# SN32F770 register map
Vendor: SONiX Technology Co., Ltd.; Series: SN32F770; File version: 1.4
CPU: CM0 r0p0, little endian, no MPU, no FPU, 2 interrupt priority bits
Registers are 32-bit, read-write, reset 0x0 unless marked. A register's access mark holds for its fields unless they carry their own. Offsets are from the block's base; [hi:lo] are bit positions; {n}, {i} and the like mark numbered series.

## SN_CT16B0 — 16-bit Timer 0 with Capture function
Base 0x40000000
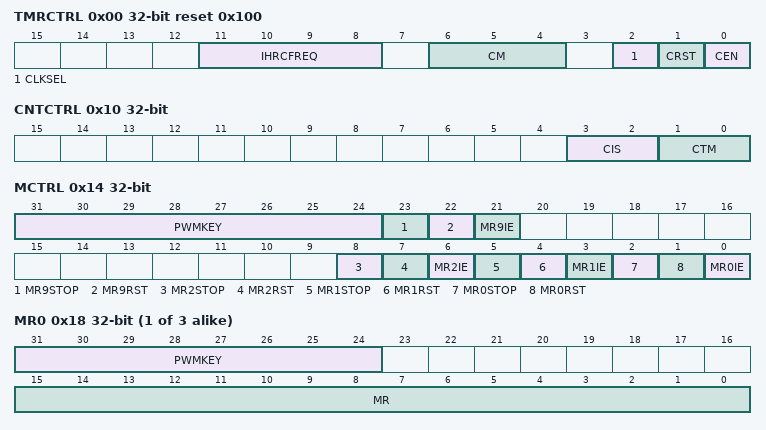
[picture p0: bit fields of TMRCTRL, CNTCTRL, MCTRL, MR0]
0x00 TMRCTRL reset 0x100 — Offset:0x00 CT16Bn Timer Control Register
  [11:8] IHRCFREQ — Internal high-speed clock frequency for CT16B0 PCLK
    1=IHRC (Enable IHRC 12MHz for CT16B0 PCLK); 2=IHRC (Enable IHRC 24MHz for CT16B0 PCLK); 4=IHRC (Enable IHRC 48MHz for CT16B0 PCLK); 8=IHRC (Enable IHRC 96MHz for CT16B0 PCLK)
  [6:4] CM — Counting mode selection
    0=Counting mode (Edge-aligned Up-counting mode); 1=Counting mode (Edge-aligned Down-counting mode); 2=Counting mode (Center-aligned mode 1. The match interrupt flag is set during the down-counting period); 4=Counting mode (Center-aligned mode 2. The match interrupt flag is set during the up- counting period); 6=Counting mode (Center-aligned mode 3. The match interrupt flag is set during both up-counting and down-counting period)
  [2] CLKSEL — Clock source
    0=HCLK (CT16Bn clock source=HCLK); 1=IHRC (CT16Bn clock source=IHRC)
  [1] CRST — Counter Reset
    0=Disable; 1=Reset Counter (Timer Counter and the Prescale Counter are synchronously reset on the next positive edge of PCLK)
  [0] CEN — Counter enable
    0=Disable counter; 1=Enable Timer Counter and Prescale Counter for counting
0x04 TC — Offset:0x04 CT16Bn Timer Counter Register
  [15:0] TC — Timer Counter
0x08 PRE — Offset:0x08 CT16Bn Prescale Register
  [7:0] PRE — Prescaler
0x0C PC — Offset:0x0C CT16Bn Prescale Counter Register
  [7:0] PC — Prescaler Counter
0x10 CNTCTRL — Offset:0x10 CT16Bn Counter Control Register
  [3:2] CIS — Counter Input Select
    0=CT16Bn_CAP0
  [1:0] CTM — Counter/Timer Mode
    0=Timer Mode: every rising PCLK edge; 1=Counter Mode:TC is incremented on rising edges on the CAP0 input selected by CIS bits; 2=Counter Mode:TC is incremented on falling edges on the CAP0 input selected by CIS bits; 3=Counter Mode:TC is incremented on both edges on the CAP0 input selected by CIS bits
0x14 MCTRL — Offset:0x14 CT16Bn Match Control Register
  [31:24] PWMKEY wo — PWM register key.
  [23] MR9STOP — Stop TC and PC and clear CEN bit when MR9 matches TC
    0=Disable; 1=Enable (Stop TC and PC and clear CEN bit when MR9 matches TC)
  [22] MR9RST — Enable reset TC when MR9 matches TC
    0=Disable; 1=Enable (Reset TC when MR9 matches TC)
  [21] MR9IE — Enable generating an interrupt based on CM[2:0] when MR9 matches the value in the TC
    0=Disable; 1=Enable (Generating an interrupt when MR9 matches TC)
  [8] MR2STOP — Stop TC and PC and clear CEN bit when MR2 matches TC
    0=Disable; 1=Enable (Stop TC and PC and clear CEN bit when MR2 matches TC)
  [7] MR2RST — Enable reset TC when MR2 matches TC
    0=Disable; 1=Enable (Reset TC when MR2 matches TC)
  [6] MR2IE — Enable generating an interrupt when MR2 matches TC
    0=Disable; 1=Enable (Generating an interrupt when MR2 matches TC)
  [5] MR1STOP — Stop TC and PC and clear CEN bit when MR1 matches TC
    0=Disable; 1=Enable (Stop TC and PC and clear CEN bit when MR1 matches TC)
  [4] MR1RST — Enable reset TC when MR1 matches TC
    0=Disable; 1=Enable (Reset TC when MR1 matches TC)
  [3] MR1IE — Enable generating an interrupt when MR1 matches TC
    0=Disable; 1=Enable (Generating an interrupt when MR1 matches TC)
  [2] MR0STOP — Stop TC and PC and clear CEN bit when MR0 matches TC
    0=Disable; 1=Enable (Stop TC and PC and clear CEN bit when MR0 matches TC)
  [1] MR0RST — Enable reset TC when MR0 matches TC
    0=Disable; 1=Enable (Reset TC when MR0 matches TC)
  [0] MR0IE — Enable generating an interrupt when MR0 matches TC
    0=Disable; 1=Enable (Generating an interrupt when MR0 matches TC)
{0x18+4i} MR{i} (i=0..2) — Offset:{0x18+4i} CT16Bn MR{i} Register
  [31:24] PWMKEY wo — PWM register key
  [15:0] MR — Timer counter match value
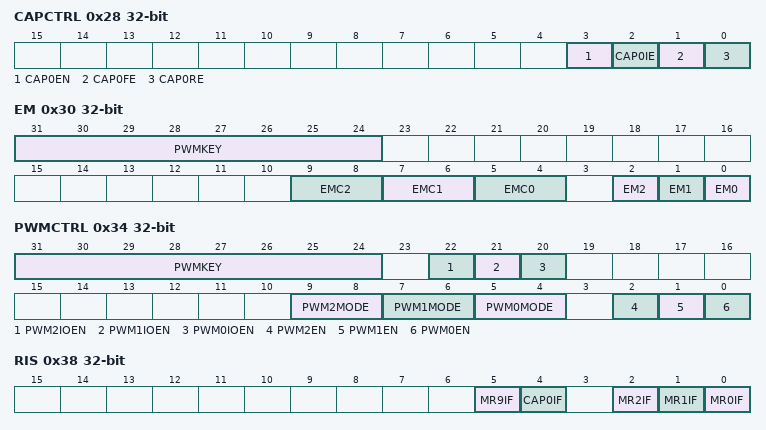
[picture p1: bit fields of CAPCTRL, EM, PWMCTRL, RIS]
0x28 CAPCTRL — Offset:0x28 CT16Bn Capture Control Register
  [3] CAP0EN — CAP0 function enable
    0=Disable; 1=Enable CAP0 function
  [2] CAP0IE — Interrupt on CT16Bn_CAP0 event
    0=Disable; 1=Enable (A CAP0 load due to a CT16Bn_CAP0 event will generate an interrupt.)
  [1] CAP0FE — Capture on CT16Bn_CAP0 falling edge
    0=Disable; 1=Enable (A sequence of 1 then 0 on CT16Bn_CAP0 will cause CAP0 to be loaded with the contents of TC.)
  [0] CAP0RE — Capture on CT16Bn_CAP0 rising edge
    0=Disable; 1=Enable (A sequence of 0 then 1 on CT16Bn_CAP0 will cause CAP0 to be loaded with the contents of TC.)
0x2C CAP0 ro — Offset:0x2C CT16Bn CAP0 Register
  [15:0] CAP0 — Timer counter capture value
0x30 EM — Offset:0x30 CT16Bn External Match Register
  [31:24] PWMKEY wo — PWM register key.
  [9:8] EMC2 — CT16Bn_PWM2 functionality when the TC matches MR2
    0=Do Nothing; 1=Low (CT16Bn_PWM2 pin is LOW); 2=High (CT16Bn_PWM2 pin is HIGH); 3=Toggle CT16Bn_PWM2 pin
  [7:6] EMC1 — CT16Bn_PWM1 functionality when the TC matches MR1
    0=Do Nothing; 1=Low (CT16Bn_PWM1 pin is LOW); 2=High (CT16Bn_PWM1 pin is HIGH); 3=Toggle CT16Bn_PWM1 pin
  [5:4] EMC0 — CT16Bn_PWM0 functionality when the TC matches MR0
    0=Do Nothing; 1=Low (CT16Bn_PWM0 pin is LOW); 2=High (CT16Bn_PWM0 pin is HIGH); 3=Toggle CT16Bn_PWM0 pin
  [2] EM2 — When the TC doesn't match MR2 and EMC2 is not 0, this bit will drive the state of CT16Bn_PWM2 output.
  [1] EM1 — When the TC doesn't match MR1 and EMC1 is not 0, this bit will drive the state of CT16Bn_PWM1 output.
  [0] EM0 — When the TC doesn't match MR0 and EMC0 is not 0, this bit will drive the state of CT16Bn_PWM0 output.
0x34 PWMCTRL — Offset:0x34 CT16Bn PWM Control Register
  [31:24] PWMKEY wo — PWM register key.
  [22] PWM2IOEN — CT16Bn_PWM2/GPIO selection
    0=Disable (CT16Bn_PWM2 pin is act as GPIO); 1=Enable (CT16Bn_PWM2 pin act as match output, and output depends on PWM2EN bit)
  [21] PWM1IOEN — CT16Bn_PWM1/GPIO selection
    0=Disable (CT16Bn_PWM1 pin is act as GPIO); 1=Enable (CT16Bn_PWM1 pin act as match output, and output depends on PWM1EN bit)
  [20] PWM0IOEN — CT16Bn_PWM0/GPIO selection
    0=Disable (CT16Bn_PWM0 pin is act as GPIO); 1=Enable (CT16Bn_PWM0 pin act as match output, and output depends on PWM0EN bit)
  [9:8] PWM2MODE — PWM2 output mode
    0=PWM mode 1 (During up-counting, PWM2 is 0 when TC is less than MR2.); 1=PWM mode 2 (During up-counting, PWM2 is 1 when TC is less than MR2.); 2=Force 0 (PWM2 is forced to 0); 3=Force 1 (PWM2 is forced to 1)
  [7:6] PWM1MODE — PWM1 output mode
    0=PWM mode 1 (During up-counting, PWM1 is 0 when TC is less than MR1.); 1=PWM mode 2 (During up-counting, PWM1 is 1 when TC is less than MR1.); 2=Force 0 (PWM1 is forced to 0); 3=Force 1 (PWM1 is forced to 1)
  [5:4] PWM0MODE — PWM0 output mode
    0=PWM mode 1 (During up-counting, PWM0 is 0 when TC is less than MR0.); 1=PWM mode 2 (During up-counting, PWM0 is 1 when TC is less than MR0.); 2=Force 0 (PWM0 is forced to 0); 3=Force 1 (PWM0 is forced to 1)
  [2] PWM2EN — PWM2 enable
    0=Disable (CT16Bn_PWM2 is controlled by EMC2); 1=Enable PWM mode for CT16Bn_PWM2
  [1] PWM1EN — PWM1 enable
    0=Disable (CT16Bn_PWM1 is controlled by EMC1); 1=Enable PWM mode for CT16Bn_PWM1
  [0] PWM0EN — PWM0 enable
    0=Disable (CT16Bn_PWM0 is controlled by EMC0); 1=Enable PWM mode for CT16Bn_PWM0
0x38 RIS ro — Offset:0x38 CT16Bn Raw Interrupt Status Register
  [5] MR9IF — Match channel 9 interrupt flag
    0=No (No interrupt on match channel 9); 1=Met interrupt requirements (Interrupt requirements met on match channel 9)
  [4] CAP0IF — Capture channel 0 interrupt flag
    0=No (No interrupt on CAP0); 1=Met interrupt requirements (Interrupt requirements met on CAP0)
  [2] MR2IF — Match channel 2 interrupt flag
    0=No (No interrupt on match channel 2); 1=Met interrupt requirements (Interrupt requirements met on match channel 2)
  [1] MR1IF — Match channel 1 interrupt flag
    0=No (No interrupt on match channel 1); 1=Met interrupt requirements (Interrupt requirements met on match channel 1)
  [0] MR0IF — Match channel 0 interrupt flag
    0=No interrupt on match channel 0; 1=Met interrupt requirements (Interrupt requirements met on match channel 0)
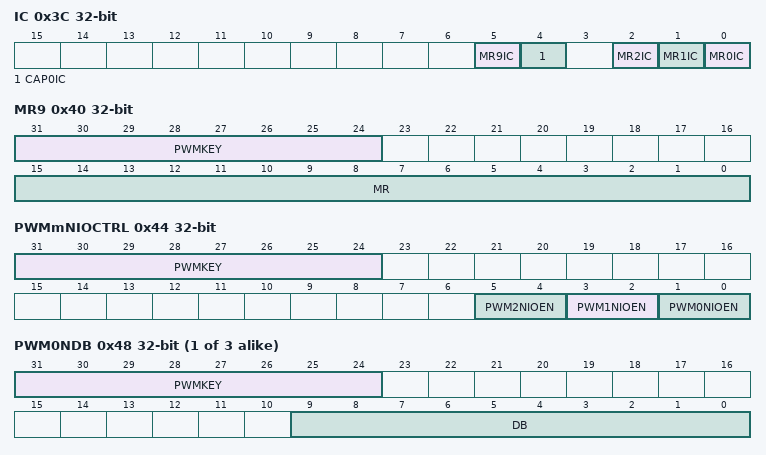
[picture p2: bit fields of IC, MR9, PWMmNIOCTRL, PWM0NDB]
0x3C IC wo — Offset:0x3C CT16Bn Interrupt Clear Register
  [5] MR9IC — MR9IF clear bit
    0=No effect; 1=Clear MR9IF
  [4] CAP0IC — CAP0IF clear bit
    0=No effect; 1=Clear CAP0IF
  [2] MR2IC — MR2IF clear bit
    0=No effect; 1=Clear MR2IF
  [1] MR1IC — MR1IF clear bit
    0=No effect; 1=Clear MR1IF
  [0] MR0IC — MR0IF clear bit
    0=No effect; 1=Clear MR0IF
0x40 MR9 — Offset:0x40 CT16Bn MR9 Register
  [31:24] PWMKEY wo — PWM register key.
  [15:0] MR — Timer counter match value
0x44 PWMmNIOCTRL — Offset:0x44 CT16Bn PWMmN IO Control register
  [31:24] PWMKEY wo — PWM register key.
  [5:4] PWM2NIOEN — CT16Bn_PWM0N/GPIO selection bit
    0=CT16Bn_PWM2N pin is act as GPIO; 1=CT16Bn_PWM2N pin outputs the inverse signal with dead-band of CT16Bn_PWM0, but same High signal during dead-band period; 2=CT16Bn_PWM2N pin outputs the inverse signal with dead-band of CT16Bn_PWM0, but same Low signal during dead-band period; 3=CT16Bn_PWM2N pin outputs the same signal with dead-band of CT16Bn_PWM0
  [3:2] PWM1NIOEN — CT16Bn_PWM0N/GPIO selection bit
    0=CT16Bn_PWM1N pin is act as GPIO; 1=CT16Bn_PWM1N pin outputs the inverse signal with dead-band of CT16Bn_PWM0, but same High signal during dead-band period; 2=CT16Bn_PWM1N pin outputs the inverse signal with dead-band of CT16Bn_PWM0, but same Low signal during dead-band period; 3=CT16Bn_PWM1N pin outputs the same signal with dead-band of CT16Bn_PWM0
  [1:0] PWM0NIOEN — CT16Bn_PWM0N/GPIO selection bit
    0=CT16Bn_PWM0N pin is act as GPIO; 1=CT16Bn_PWM0N pin outputs the inverse signal with dead-band of CT16Bn_PWM0, but same High signal during dead-band period; 2=CT16Bn_PWM0N pin outputs the inverse signal with dead-band of CT16Bn_PWM0, but same Low signal during dead-band period; 3=CT16Bn_PWM0N pin outputs the same signal with dead-band of CT16Bn_PWM0
{0x48+4i} PWM{i}NDB (i=0..2) — Offset:{0x48+4i} CT16Bn PWM{i}N Dead-band Period Register
  [31:24] PWMKEY wo — PWM register key.
  [9:0] DB — PWM{i}N output dead-band period time=DB*CT16Bn_PCLK cycle
